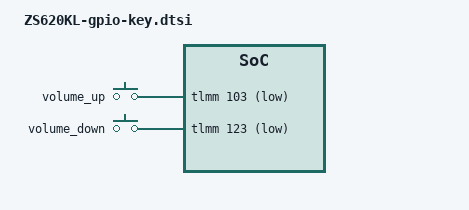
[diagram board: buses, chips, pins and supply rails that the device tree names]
&soc {

/delete-node/ gpio_keys;
/delete-node/ pcie1;

	gpio_keys {
		status = "okay";
		compatible = "gpio-keys";
		input-name = "gpio-keys";
		pinctrl-names = "tlmm_gpio_key_active","tlmm_gpio_key_suspend";
		pinctrl-0 = <&gpio_key_active>;
		pinctrl-1 = <&gpio_key_suspend>;

		vol_up {
			label = "volume_up";
			gpios = <&tlmm 103 0x1>;
			linux,input-type = <1>;
			linux,code = <115>;
			gpio-key,wakeup;
			debounce-interval = <15>;
		};

		vol_down {
			label = "volume_down";
			gpios = <&tlmm 123 0x1>;
			linux,input-type = <1>;
			linux,code = <114>;
			gpio-key,wakeup;
			debounce-interval = <15>;
		};
	};
};
